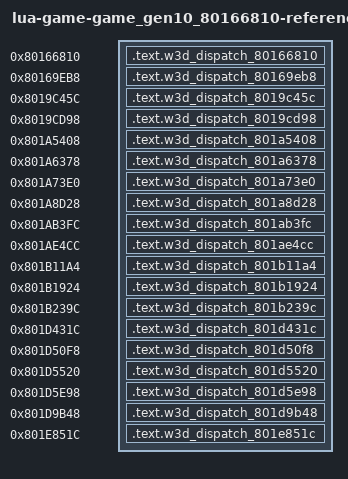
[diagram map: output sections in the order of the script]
/* Generated reference-only placements. All bodies are source-built. */
OUTPUT_FORMAT("elf32-powerpc")
OUTPUT_ARCH(powerpc)
ENTRY(w3d_dispatch_80166810)
_SDA_BASE_ = 0x804b2540;
_SDA2_BASE_ = 0x804c2540;
SECTIONS {
  .text.w3d_dispatch_80166810 0x80166810 : { *(.text.w3d_dispatch_80166810) }
  .text.w3d_dispatch_80169eb8 0x80169eb8 : { *(.text.w3d_dispatch_80169eb8) }
  .text.w3d_dispatch_8019c45c 0x8019c45c : { *(.text.w3d_dispatch_8019c45c) }
  .text.w3d_dispatch_8019cd98 0x8019cd98 : { *(.text.w3d_dispatch_8019cd98) }
  .text.w3d_dispatch_801a5408 0x801a5408 : { *(.text.w3d_dispatch_801a5408) }
  .text.w3d_dispatch_801a6378 0x801a6378 : { *(.text.w3d_dispatch_801a6378) }
  .text.w3d_dispatch_801a73e0 0x801a73e0 : { *(.text.w3d_dispatch_801a73e0) }
  .text.w3d_dispatch_801a8d28 0x801a8d28 : { *(.text.w3d_dispatch_801a8d28) }
  .text.w3d_dispatch_801ab3fc 0x801ab3fc : { *(.text.w3d_dispatch_801ab3fc) }
  .text.w3d_dispatch_801ae4cc 0x801ae4cc : { *(.text.w3d_dispatch_801ae4cc) }
  .text.w3d_dispatch_801b11a4 0x801b11a4 : { *(.text.w3d_dispatch_801b11a4) }
  .text.w3d_dispatch_801b1924 0x801b1924 : { *(.text.w3d_dispatch_801b1924) }
  .text.w3d_dispatch_801b239c 0x801b239c : { *(.text.w3d_dispatch_801b239c) }
  .text.w3d_dispatch_801d431c 0x801d431c : { *(.text.w3d_dispatch_801d431c) }
  .text.w3d_dispatch_801d50f8 0x801d50f8 : { *(.text.w3d_dispatch_801d50f8) }
  .text.w3d_dispatch_801d5520 0x801d5520 : { *(.text.w3d_dispatch_801d5520) }
  .text.w3d_dispatch_801d5e98 0x801d5e98 : { *(.text.w3d_dispatch_801d5e98) }
  .text.w3d_dispatch_801d9b48 0x801d9b48 : { *(.text.w3d_dispatch_801d9b48) }
  .text.w3d_dispatch_801e851c 0x801e851c : { *(.text.w3d_dispatch_801e851c) }
  /DISCARD/ : { *(.text*) *(.rodata*) *(.data*) *(.bss*) *(.sdata*) *(.sbss*) *(.comment) }
}
